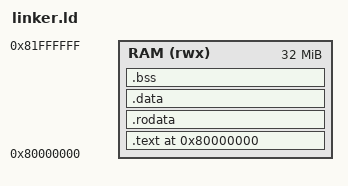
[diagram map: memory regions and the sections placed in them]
OUTPUT_ARCH("riscv")
ENTRY(_start)

MEMORY
{
    RAM (rwx) : ORIGIN = 0x80000000, LENGTH = 32M
}

SECTIONS
{
    . = 0x80000000;

    .text : {
        *(.text.boot)
        *(.text .text.*)
    } > RAM

    .rodata : {
        . = ALIGN(4);
        *(.rodata .rodata.*)
        *(.srodata .srodata.*)
    } > RAM

    .data : {
        . = ALIGN(4);
        *(.data .data.*)
        *(.sdata .sdata.*)
    } > RAM

    .bss : {
        . = ALIGN(4);
        __bss_start = .;
        *(.bss .bss.*)
        *(.sbss .sbss.*)
        *(COMMON)
        __bss_end = .;
    } > RAM

    . = ALIGN(4096);
    __kernel_heap_start = .;
}
